# PIC32CX1025MTSH128S1 register map
Vendor: Microchip Technology; Series: PIC32CXMTSH; File version: 0
Microchip PIC32CX1025MTSH128S1 Microcontroller
CPU: CM4 r0p1, selectable endian, MPU, FPU, 4 interrupt priority bits
Registers are 32-bit, read-write, reset 0x0 unless marked. A register's access mark holds for its fields unless they carry their own. Offsets are from the block's base; lines under a group give offsets from that group; [hi:lo] are bit positions; {n}, {i} and the like mark numbered series; 'fields as' and 'values as' point back to an identical list; <NAME> marks a mode.

## Memory map
0x40000000 FLEXCOM0 size 0x6EC — Flexible Serial Communication
0x40004000 FLEXCOM1 size 0x6EC
0x40008000 FLEXCOM2 size 0x6EC
0x4000C000 FLEXCOM3 size 0x6EC
0x40010000 FLEXCOM4 size 0x6EC
0x40014000 FLEXCOM5 size 0x6EC
0x40018000 FLEXCOM6 size 0x6EC
0x4001C000 FLEXCOM7 size 0x6EC
0x40020000 QSPI size 0x12C — Quad Serial Peripheral Interface
0x40024000 ADC size 0x154 — Analog-to-Digital Converter
0x40028000 ACC size 0xEC — Analog Comparator Controller
0x4002C000 IPC0 size 0x20 — Inter-processor Communication
0x40030000 SLCDC size 0x23C — Segment LCD Controller
0x40034000 MEM2MEM0 size 0x12C — Memory to Memory
0x40038000 TC0 size 0x12C — Timer Counter
0x4003C000 TC1 size 0x12C
0x40040000 TC2 size 0x12C
0x40044000 MATRIX1 size 0x2CC — AHB Bus Matrix
0x40048000 PIO0 size 0x15E8 — Parallel Input/Output Controller
0x40050200 CHIPID size 0x8 — Chip Identifier
0x40050400 SFR size 0x100 — Special Function Register
0x40050600 SFRBU size 0xF4 — Special Function Register Backup
0x40052000 DWDT size 0x1240 — Dual Watchdog Timer
0x40053000 RSTC size 0xC — Reset Controller
0x40053020 RTT size 0x14 — Real-time Timer
0x40053060 GPBR size 0x98 — General Purpose Backup Registers
0x40053100 RTC size 0xAE — Real-time Clock
0x400531A0 SYSCWP size 0x8 — External Interrupt Controller
0x400531D0 SUPC size 0x38 — Supply Controller
0x46800000 PMC size 0xF8 — Power Management Controller
0x48000000 EMAFE size 0x12C — Energy Metering Analog Front End
0x48004000 MEM2MEM1 size 0x12C
0x48008000 TC3 size 0x12C
0x4800C000 PIO1 size 0x15E8
0x48010000 UART size 0x12C — Universal Asynchronous Receiver Transmitter
0x48014000 IPC1 size 0x20
0x48018000 MCSPI size 0x12C — Multi Channel Serial Peripheral Interface
0x4801C000 PWM size 0x454 — Pulse Width Modulation Controller
0x48020000 MATRIX3 size 0x2CC
0x4A000000 MATRIX2 size 0x2CC
0xE0000000 ITM size 0xF00 — Instrumentation Trace Macrocell
0xE0001000 DWT size 0x5C — Data Watchpoint and Trace Register
0xE000E000 SystemControl size 0xD8C — System Control Registers
0xE000E010 SysTick size 0x10 — System timer
0xE000E100 NVIC size 0xE04 — Nested Vectored Interrupt Controller
0xE000ED90 MPU size 0x2C — Memory Protection Unit
0xE000EDF0 CoreDebug size 0x10
0xE000EF30 FPU size 0x18 — Floating Point Unit
0xE0040000 TPI size 0xFD0 — Trace Port Interface Register

## Interrupts
0 SUPC
1 RSTC
2 RTC
3 RTT
4 DWDT0 (DWDT)
5 DWDT1 (DWDT)
6 PMC
{n+9} FLEXCOM{n} (n=0..7)
23 QSPI
24 ADC
25 ACC
28 IPC0
29 SLCDC
30 MEM2MEM0
31 TC0_CHANNEL0 (TC0)
32 TC0_CHANNEL1 (TC0)
33 TC0_CHANNEL2 (TC0)
34 TC1_CHANNEL0 (TC1)
35 TC1_CHANNEL1 (TC1)
36 TC1_CHANNEL2 (TC1)
37 TC2_CHANNEL0 (TC2)
38 TC2_CHANNEL1 (TC2)
39 TC2_CHANNEL2 (TC2)
40 TC0_C0SEC (TC0)
41 TC0_C1SEC (TC0)
42 TC0_C2SEC (TC0)
43 TC1_C0SEC (TC1)
44 TC1_C1SEC (TC1)
45 TC1_C2SEC (TC1)
46 TC2_C0SEC (TC2)
47 TC2_C1SEC (TC2)
48 TC2_C2SEC (TC2)
61 MATRIX1
{n+59} SUPC_WKUP{n} (SUPC) (n=3..15)
76 EMAFE_SLINK (EMAFE)
77 EMAFE_DATA (EMAFE)
78 MEM2MEM1
79 TC3_CHANNEL0 (TC3)
80 TC3_CHANNEL1 (TC3)
81 TC3_CHANNEL2 (TC3)
82 TC3_C0SEC (TC3)
83 TC3_C1SEC (TC3)
84 TC3_C2SEC (TC3)
87 UART
88 IPC1
89 MCSPI
90 PWM
94 MATRIX2
95 MATRIX3

## ACC — Analog Comparator Controller
Base 0x40028000; register names take the prefix ACC_
0x00 CR wo — Control Register
  [0] SWRST — Software Reset
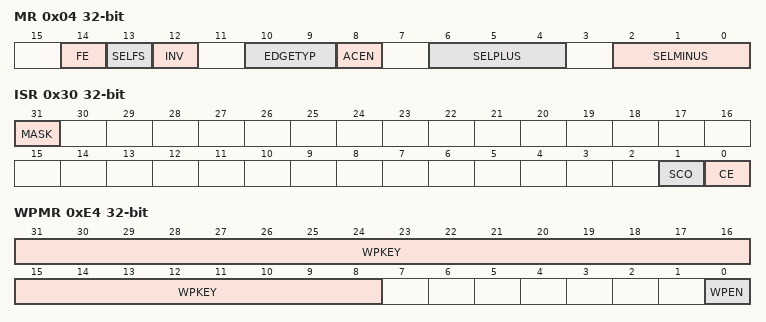
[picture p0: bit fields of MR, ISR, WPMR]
0x04 MR — Mode Register
  [14] FE — Fault Enable
    0=DIS (The FAULT output is tied to 0.); 1=EN (The FAULT output is driven by the signal defined by SELFS.)
  [13] SELFS — Selection Of Fault Source
    0=CE (The CE flag is used to drive the FAULT output.); 1=OUTPUT (The output of the analog comparator flag is used to drive the FAULT output.)
  [12] INV — Invert Comparator Output
    0=DIS (Analog comparator output is directly processed.); 1=EN (Analog comparator output is inverted prior to being processed.)
  [10:9] EDGETYP — Edge Type
    0=RISING (Only rising edge of comparator output); 1=FALLING (Falling edge of comparator output); 2=ANY (Any edge of comparator output)
  [8] ACEN — Analog Comparator Enable
    0=DIS (Analog comparator disabled.); 1=EN (Analog comparator enabled.)
  [6:4] SELPLUS — Selection For Plus Comparator Input
    0=AD0 (Selects AD0); 1=AD1 (Selects AD1); 2=AD2 (Selects AD2); 3=VREFP (Selects VREFP)
  [2:0] SELMINUS — Selection for Minus Comparator Input
    0=AD3 (Selects AD3); 1=AD4 (Selects AD4); 2=VTEMP (Selects VTEMP); 3=VREFTEMP (Selects VREFTEMP)
0x24 IER wo — Interrupt Enable Register
  [0] CE — Comparison Edge
0x28 IDR wo — Interrupt Disable Register
  [0] CE — Comparison Edge
0x2C IMR ro — Interrupt Mask Register
  [0] CE — Comparison Edge
0x30 ISR ro — Interrupt Status Register
  [31] MASK — Flag Mask
  [1] SCO — Synchronized Comparator Output
  [0] CE — Comparison Edge (cleared on read)
0x94 ACR — Analog Control Register
  [0] MSEL — Masking Period Selection
    0=Masks AC output for 16 peripheral clock periods after any write access in ACC_MR or ACC_CR; 1=Masks AC output for 128 peripheral clock periods after any write access in ACC_MR or ACC_CR
0xE4 WPMR — Write Protection Mode Register
  [31:8] WPKEY — Write Protection Key
    0x414343=PASSWD (Writing any other value in this field aborts the write operation of the WPEN bit. Always reads as 0.)
  [0] WPEN — Write Protection Configuration Enable
0xE8 WPSR ro — Write Protection Status Register
  [0] WPVS — Write Protection Violation Status

## Notices in the file
Copyright (c) 2017 Microchip Technology Inc.
SPDX-License-Identifier: Apache-2.0
Licensed under the Apache License, Version 2.0 (the "License");
you may not use this file except in compliance with the License.
You may obtain a copy of the License at
http://www.apache.org/licenses/LICENSE-2.0
Unless required by applicable law or agreed to in writing, software
distributed under the License is distributed on an "AS IS" BASIS,
WITHOUT WARRANTIES OR CONDITIONS OF ANY KIND, either express or implied.
See the License for the specific language governing permissions and
limitations under the License.
